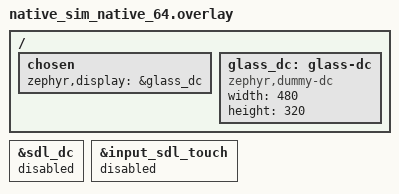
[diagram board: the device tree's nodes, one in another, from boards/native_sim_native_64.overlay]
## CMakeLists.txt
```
# GlassVGL demo for Zephyr. Build it from your west workspace:
#   west build -b native_sim/native/64 path/to/GlassVGL/examples/zephyr
# This file adds the GlassVGL pack as a module by itself, so the workspace only needs Zephyr and
# LVGL. It looks for a GlassVGL-Pro checkout next to this repository; pass -DGLASSVGL_DIR=... to
# use another place.
cmake_minimum_required(VERSION 3.20.0)
set(GLASSVGL_DIR "${CMAKE_CURRENT_SOURCE_DIR}/../../../GlassVGL-Pro" CACHE PATH "the GlassVGL pack")
list(APPEND EXTRA_ZEPHYR_MODULES ${GLASSVGL_DIR})
find_package(Zephyr REQUIRED HINTS $ENV{ZEPHYR_BASE})
project(glassvgl_zephyr_demo)
target_sources(app PRIVATE src/main.c)
```

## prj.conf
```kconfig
CONFIG_DISPLAY=y
CONFIG_LVGL=y
CONFIG_GLASSVGL=y
CONFIG_MAIN_STACK_SIZE=8192

# The glass buffers come from the C library heap. LVGL's own small pool is too small for them.
CONFIG_LV_Z_MEM_POOL_HEAP_LIB_C=y
# On a real board also give the C library a heap big enough for the mode you want, e.g.
# CONFIG_COMMON_LIBC_MALLOC_ARENA_SIZE=4194304 (native_sim uses the host C library instead).

CONFIG_LV_USE_THEME_DEFAULT=y
CONFIG_LV_USE_SNAPSHOT=y
CONFIG_LV_FONT_MONTSERRAT_12=y
CONFIG_LV_FONT_MONTSERRAT_14=y
CONFIG_LV_FONT_MONTSERRAT_16=y
CONFIG_LV_FONT_MONTSERRAT_20=y
CONFIG_LV_FONT_MONTSERRAT_28=y
CONFIG_LV_FONT_MONTSERRAT_48=y
CONFIG_LV_USE_LOG=y
CONFIG_LOG=y
```

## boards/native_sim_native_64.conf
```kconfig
# The dummy display below takes 32-bit pixels.
CONFIG_LV_COLOR_DEPTH_32=y
CONFIG_SDL_DISPLAY=n
CONFIG_INPUT=n
```

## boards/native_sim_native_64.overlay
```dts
/* Build check on a PC with no SDL: draw into Zephyr's dummy display instead of an SDL window. */
/ {
	chosen {
		zephyr,display = &glass_dc;
	};

	glass_dc: glass-dc {
		compatible = "zephyr,dummy-dc";
		width = <480>;
		height = <320>;
	};
};

&sdl_dc {
	status = "disabled";
};

&input_sdl_touch {
	status = "disabled";
};
```

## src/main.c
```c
/*
 * GlassVGL demo for Zephyr. Zephyr's LVGL module creates the display from the devicetree's
 * zephyr,display node; this sets the glass theme on it and cycles the six demo screens.
 */
#include <zephyr/kernel.h>
#include <zephyr/device.h>
#include <zephyr/drivers/display.h>
#include <zephyr/logging/log.h>
#include <lvgl.h>
#include "lv_glass.h"
#include "demo/lv_glass_demo.h"

LOG_MODULE_REGISTER(glassvgl_demo, LOG_LEVEL_INF);

int main(void)
{
    const struct device * display = DEVICE_DT_GET(DT_CHOSEN(zephyr_display));
    if(!device_is_ready(display)) {
        LOG_ERR("display not ready");
        return 0;
    }

    lv_glass_config_t cfg;
    lv_glass_config_init(&cfg);
    cfg.scheme = LV_GLASS_SCHEME_DARK;
    cfg.accent = LV_GLASS_ACCENT_AZURE;
    cfg.wallpaper = LV_GLASS_WALLPAPER_GRAPHITE;
    lv_glass_theme_init(lv_display_get_default(), &cfg);

    lv_glass_stats_t st;
    lv_glass_get_stats(&st);
    LOG_INF("GlassVGL: mode %s, bake %u ms", lv_glass_mode_name(st.mode), (unsigned)st.bake_ms);

    lv_glass_demo_start(5000);
    display_blanking_off(display);

    while(1) {
        uint32_t sleep_ms = lv_timer_handler();
        k_msleep(MIN(sleep_ms, 50));
    }
    return 0;
}
```
